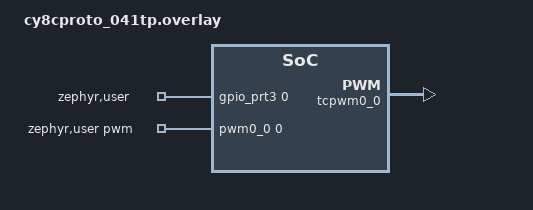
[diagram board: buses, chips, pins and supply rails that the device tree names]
/*
 * Copyright (c) 2026 Infineon Technologies AG
 *
 * SPDX-License-Identifier: Apache-2.0
 */

#include <zephyr/dt-bindings/pwm/pwm.h>
#include <zephyr/dt-bindings/pwm/pwm_ifx_tcpwm.h>

/ {
	zephyr,user {
		/* PWM out on P3.1, GPIO in on P3.0.
		 * These pins must be physically connected for the test to pass.
		 */
		pwms = <&pwm0_0 0 PWM_MSEC(2) (PWM_POLARITY_NORMAL | PWM_IFX_TCPWM_OUTPUT_HIGHZ)>;
		gpios = <&gpio_prt3 0 GPIO_ACTIVE_HIGH>;
	};
};

&tcpwm0_0 {
	status = "okay";

	pwm0_0: pwm0_0 {
		compatible = "infineon,tcpwm-pwm";
		status = "okay";
		clocks = <&peri_clk_div3>;
		pinctrl-0 = <&p3_1_pwm0_0>;
		pinctrl-names = "default";
	};
};

&peri_clk_div3 {
	status = "okay";
	resource-type = <IFX_RSC_TCPWM>;
	resource-instance = <0>;
	resource-channel = <0>;
	clock-div = <24>;
};

&pinctrl {
	p3_1_pwm0_0: p3_1_pwm0_0 {
		drive-push-pull;
	};
};

&gpio_prt3 {
	status = "okay";
};
